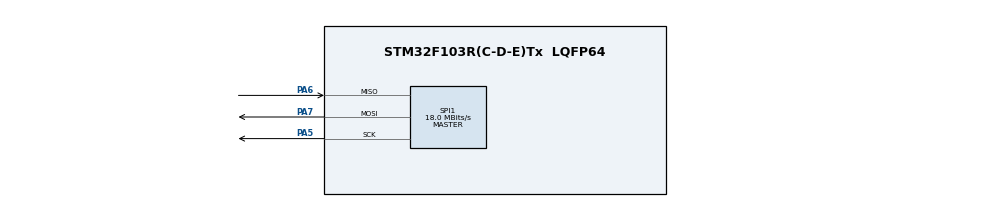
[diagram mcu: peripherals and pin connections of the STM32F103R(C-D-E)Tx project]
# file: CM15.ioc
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Mcu.Family=STM32F1
Mcu.Name=STM32F103R(C-D-E)Tx
Mcu.Package=LQFP64
NVIC.PriorityGroup=NVIC_PRIORITYGROUP_4
PA13.Mode=Serial_Wire
PA13.Signal=SYS_JTMS-SWDIO
PA14.Mode=Serial_Wire
PA14.Signal=SYS_JTCK-SWCLK
PA5.Mode=Full_Duplex_Master
PA5.Signal=SPI1_SCK
PA6.Mode=Full_Duplex_Master
PA6.Signal=SPI1_MISO
PA7.Mode=Full_Duplex_Master
PA7.Signal=SPI1_MOSI
PD0-OSC_IN.Mode=HSE-External-Oscillator
PD0-OSC_IN.Signal=RCC_OSC_IN
PD1-OSC_OUT.Mode=HSE-External-Oscillator
PD1-OSC_OUT.Signal=RCC_OSC_OUT
ProjectManager.HeapSize=0x200
ProjectManager.StackSize=0x400
ProjectManager.TargetToolchain=MDK-ARM V5.32
RCC.AHBFreq_Value=72000000
RCC.APB1CLKDivider=RCC_HCLK_DIV2
RCC.APB1Freq_Value=36000000
RCC.APB1TimFreq_Value=72000000
RCC.APB2Freq_Value=72000000
RCC.APB2TimFreq_Value=72000000
RCC.HCLKFreq_Value=72000000
RCC.PLLMUL=RCC_PLL_MUL9
RCC.PLLSourceVirtual=RCC_PLLSOURCE_HSE
RCC.SYSCLKFreq_VALUE=72000000
RCC.SYSCLKSource=RCC_SYSCLKSOURCE_PLLCLK
RCC.USBFreq_Value=72000000
SPI1.BaudRatePrescaler=SPI_BAUDRATEPRESCALER_4
SPI1.CalculateBaudRate=18.0 MBits/s
SPI1.Direction=SPI_DIRECTION_2LINES
SPI1.Mode=SPI_MODE_MASTER
SPI1.VirtualType=VM_MASTER
board=custom

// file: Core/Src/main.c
/* USER CODE BEGIN Header */
/**
  ******************************************************************************
  * @file           : main.c
  * @brief          : Main program body
  ******************************************************************************
  * @attention
  *
  * Copyright (c) 2023 STMicroelectronics.
  * All rights reserved.
  *
  * This software is licensed under terms that can be found in the LICENSE file
  * in the root directory of this software component.
  * If no LICENSE file comes with this software, it is provided AS-IS.
  *
  ******************************************************************************
  */
/* USER CODE END Header */
#include "main.h"
#include "spi.h"
#include "gpio.h"

/* USER CODE BEGIN PD */
#define KSP_DRILL
/* USER CODE END PD */

void SystemClock_Config(void);

/* USER CODE BEGIN 0 */
bool motorSpin = false;
bool openDoor = false;
uint16_t _timer = 300;
int dx = 1;
uint8_t _cnt = 0;
uint8_t mode = 1;
uint8_t tx_buf[256*64];
uint32_t ris = 0;
uint32_t fal = 0;
uint8_t numBuf[11] = {0};

/* USER CODE END 0 */

int main(void)
{

  /* MCU Configuration--------------------------------------------------------*/

  /* Reset of all peripherals, Initializes the Flash interface and the Systick. */
  LL_APB2_GRP1_EnableClock(LL_APB2_GRP1_PERIPH_AFIO);
  LL_APB1_GRP1_EnableClock(LL_APB1_GRP1_PERIPH_PWR);

  /* System interrupt init*/
  NVIC_SetPriorityGrouping(NVIC_PRIORITYGROUP_4);

  /* SysTick_IRQn interrupt configuration */
  NVIC_SetPriority(SysTick_IRQn, NVIC_EncodePriority(NVIC_GetPriorityGrouping(),15, 0));

  /** NOJTAG: JTAG-DP Disabled and SW-DP Enabled
  */
  LL_GPIO_AF_Remap_SWJ_NOJTAG();

  /* Configure the system clock */
  SystemClock_Config();

  /* Initialize all configured peripherals */
  MX_GPIO_Init();
  MX_SPI1_Init();
  /* USER CODE BEGIN 2 */
  #ifndef KSP_DRILL
  ST7565_Init();
  InitGUI();
  #endif

  #ifdef KSP_DRILL

  SSD1322_API_init();
  #endif
  /* USER CODE END 2 */

  /* Infinite loop */
  /* USER CODE BEGIN WHILE */
  while (1)
  {
    fill_buffer(tx_buf, 0);

    DrawDrillWidget(false, tx_buf, 2000, 1000);

    DrawAbsIncWidget(tx_buf, 10, 0);

    DrawCntWidget(tx_buf, 0);

    send_buffer_to_OLED(tx_buf, 0, 0);
    /* USER CODE END WHILE */

  }
}

uint8_t* intToStr (uint32_t num){
	for(int i = 0; i <sizeof(numBuf); i++){
		numBuf[i] = 0;
	}
	uint32_t modNum = num;
	uint8_t ch = 0;
	uint32_t mod = 1000000000;
	if (num == 0){
		numBuf[0] = 48;
		return numBuf;
	}
	uint8_t i = 0;
	while(modNum < mod){
		mod /= 10;
	}
	if (mod == 0) {
		mod = 1;
	}

	while (modNum > 0 || mod > 0){
		while (modNum>=mod){
			ch++;
			modNum -= mod;
		}
		numBuf[i++] = ch + 48;
		ch = 0;
		mod /= 10;
//		if (mod == 0) {
//		mod = 1;
//		}
	}
	return numBuf;
}
void SystemClock_Config(void)
{
  LL_FLASH_SetLatency(LL_FLASH_LATENCY_2);
  while(LL_FLASH_GetLatency()!= LL_FLASH_LATENCY_2)
  {
  }
  LL_RCC_HSE_Enable();

   /* Wait till HSE is ready */
  while(LL_RCC_HSE_IsReady() != 1)
  {

  }
  LL_RCC_PLL_ConfigDomain_SYS(LL_RCC_PLLSOURCE_HSE_DIV_1, LL_RCC_PLL_MUL_9);
  LL_RCC_PLL_Enable();

   /* Wait till PLL is ready */
  while(LL_RCC_PLL_IsReady() != 1)
  {

  }
  LL_RCC_SetAHBPrescaler(LL_RCC_SYSCLK_DIV_1);
  LL_RCC_SetAPB1Prescaler(LL_RCC_APB1_DIV_2);
  LL_RCC_SetAPB2Prescaler(LL_RCC_APB2_DIV_1);
  LL_RCC_SetSysClkSource(LL_RCC_SYS_CLKSOURCE_PLL);

   /* Wait till System clock is ready */
  while(LL_RCC_GetSysClkSource() != LL_RCC_SYS_CLKSOURCE_STATUS_PLL)
  {

  }
  LL_Init1msTick(72000000);
  LL_SetSystemCoreClock(72000000);
}

void Error_Handler(void)
{
  __disable_irq();
  while (1)
  {
  }
}
